# SSE315 register map
Vendor: ARM Ltd.; Series: ARMv8.1-M Mainline; File version: 1.0
CPU: CM85 r0p0, little endian, MPU, FPU, 3 interrupt priority bits, 8 SAU regions
Registers are 32-bit, read-write, reset 0x0 unless marked. A register's access mark holds for its fields unless they carry their own. Offsets are from the block's base; [hi:lo] are bit positions; {n}, {i} and the like mark numbered series.

## SAU — Security Attribution Unit
Base 0xE000EDD0
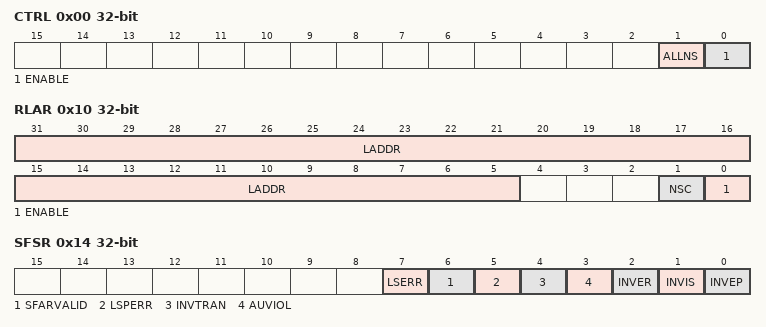
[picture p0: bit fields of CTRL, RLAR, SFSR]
0x00 CTRL — Control Register
  [1] ALLNS — Security attribution if SAU disabled
    0=Secure (Memory is marked as secure); 1=Non_Secure (Memory is marked as non-secure)
  [0] ENABLE
    0=Disable (SAU is disabled); 1=Enable (SAU is enabled)
0x04 TYPE ro
  [7:0] SREGION — Number of implemented SAU regions
0x08 RNR — Region Number Register
  [7:0] REGION — Currently selected SAU region
    {v}=SAU_Region_{v} (Select SAU Region {v}) (v=0..3)
0x0C RBAR — Region Base Address Register
  [31:5] BADDR — Base Address
0x10 RLAR — Region Limit Address Register
  [31:5] LADDR — Limit Address
  [1] NSC — Non-Secure Callable
  [0] ENABLE — SAU Region enabled
0x14 SFSR — Secure Fault Status Register
  [7] LSERR — Lazy state error flag
  [6] SFARVALID — Secure fault address valid
  [5] LSPERR — Lazy state preservation error flag
  [4] INVTRAN — Invalid transition flag
  [3] AUVIOL — Attribution unit violation flag
  [2] INVER — Invalid exception return flag
  [1] INVIS — Invalid integrity signature flag
  [0] INVEP — Invalid entry pointd

## TIMER0
Base 0x48000000
Same registers: TIMER1 0x48001000, TIMER2 0x48002000, TIMER3 0x48003000, TIMER0_Secure 0x58000000, TIMER1_Secure 0x58001000, TIMER2_Secure 0x58002000, TIMER3_Secure 0x58003000
0x00 CNTPCTLOW ro — Physical Count Register Lower Word.
0x04 CNTPCTHIGH ro — Physical Count Register Higher Word.
0x10 CNTFRQ — Counter Frequency Register.
0x20 CNTP_CVAL_LOW — Timer Compare Value Lower Word Register.
0x24 CNTP_CVAL_HIGH — Timer Compare Value Higher Word Register.
0x28 CNTP_TVAL — Timer Value register.
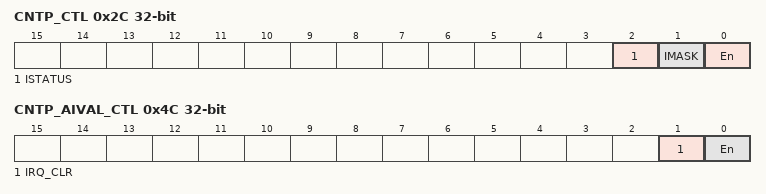
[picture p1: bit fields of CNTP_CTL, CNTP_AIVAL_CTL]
0x2C CNTP_CTL — Timer Control register.
  [all] fields
    0=Off; 1=On
  [2] ISTATUS — Interrupt Status
  [1] IMASK — Interrupt Mask
  [0] En — Enable Counter
0x40 CNTP_AIVAL_LOW ro — AutoIncrValue Lower Word Register.
0x44 CNTP_AIVAL_HIGH ro — AutoIncrValue Higher Word Register.
0x48 CNTP_AIVAL_RELOAD — AutoIncrValue Reload register.
0x4C CNTP_AIVAL_CTL — AutoIncrValue Control register.
  [1] IRQ_CLR — Interrupt Clear
    0=Nop; 1=Clear
  [0] En — Enable AutoIncrement.
    0=Off; 1=On
0x50 CNTP_CFG — Timer Configuration register.
0xFD0 PIDR4 ro reset 0x4 — Peripheral ID 4
0xFE0 PIDR0 ro reset 0xB7 — Peripheral ID 0
0xFE4 PIDR1 ro reset 0xB0 — Peripheral ID 1
0xFE8 PIDR2 ro reset 0xB — Peripheral ID 2
0xFEC PIDR3 ro — Peripheral ID 3
0xFF0 CIDR0 ro reset 0xD — Component ID 0
0xFF4 CIDR1 ro reset 0xF0 — Component ID 1
0xFF8 CIDR2 ro reset 0x5 — Component ID 2
0xFFC CIDR3 ro reset 0xB1 — Component ID 3

## SLOWCLK — SLOWCLK AON Timer
Base 0x4802F000
Same registers: SLOWCLKWATCHDOG 0x5802E000, SLOWCLK_Secure 0x5802F000
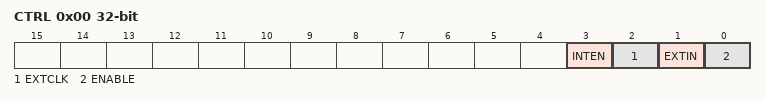
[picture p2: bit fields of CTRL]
0x00 CTRL — Control Register
  [3] INTEN — Interrupt Enable
    0=Disable (Interrupt is disabled); 1=Enable (Interrupt is enabled)
  [2] EXTCLK — External Clock Enable
    0=Disable (External Clock is disabled); 1=Enable (External Clock is enabled)
  [1] EXTIN — External Input as Enable
    0=Disable (External Input as Enable is disabled); 1=Enable (External Input as Enable is enabled)
  [0] ENABLE
    0=Disable (Timer is disabled); 1=Enable (Timer is enabled)
0x04 VALUE — Current Timer Counter Value
0x08 RELOAD — Counter Reload Value
0x0C INTSTATUS ro — Timer Interrupt status register
0x0C INTCLEAR wo write-1-clears (alternate view of INTSTATUS) — Timer Interrupt clear register

## GPIO0 — General-purpose I/O 0
Base 0x41100000
Same registers: GPIO1 0x41101000, GPIO2 0x41102000, GPIO3 0x41103000, GPIO0_Secure 0x50100000, GPIO1_Secure 0x50101000, GPIO2_Secure 0x50102000, GPIO3_Secure 0x50103000
0x00 DATA
0x04 DATAOUT — Data Output Register
0x10 OUTENSET — Ouptut enable set Register
0x14 OUTENCLR — Ouptut enable clear Register
0x18 ALTFUNCSET — Alternate function set Register
0x1C ALTFUNCCLR — Alternate function clear Register
0x20 INTENSET — Interrupt enable set Register
0x24 INTENCLR — Interrupt enable clear Register
0x28 INTTYPESET — Interrupt type set Register
0x2C INTTYPECLR — Interrupt type clear Register
0x30 INTPOLSET — Polarity-level, edge interrupt configuration set Register
0x34 INTPOLCLR — Polarity-level, edge interrupt configuration clear Register
0x38 INTSTATUS ro — Interrupt Status Register
0x38 INTCLEAR wo write-1-clears (alternate view of INTSTATUS) — Interrupt CLEAR Register

## Notices in the file
Copyright (C) 2012-2022 ARM Limited. All rights reserved.
Purpose: System Viewer Description (SVD) Example (Schema Version 1.1)
This is a description of a none-existent and incomplete device
for demonstration purposes only.
Redistribution and use in source and binary forms, with or without
modification, are permitted provided that the following conditions are met:
- Redistributions of source code must retain the above copyright
notice, this list of conditions and the following disclaimer.
- Redistributions in binary form must reproduce the above copyright
notice, this list of conditions and the following disclaimer in the
documentation and/or other materials provided with the distribution.
- Neither the name of ARM nor the names of its contributors may be used
to endorse or promote products derived from this software without
specific prior written permission.
THIS SOFTWARE IS PROVIDED BY THE COPYRIGHT HOLDERS AND CONTRIBUTORS "AS IS"
AND ANY EXPRESS OR IMPLIED WARRANTIES, INCLUDING, BUT NOT LIMITED TO, THE
IMPLIED WARRANTIES OF MERCHANTABILITY AND FITNESS FOR A PARTICULAR PURPOSE
ARE DISCLAIMED. IN NO EVENT SHALL COPYRIGHT HOLDERS AND CONTRIBUTORS BE
LIABLE FOR ANY DIRECT, INDIRECT, INCIDENTAL, SPECIAL, EXEMPLARY, OR
CONSEQUENTIAL DAMAGES (INCLUDING, BUT NOT LIMITED TO, PROCUREMENT OF
SUBSTITUTE GOODS OR SERVICES; LOSS OF USE, DATA, OR PROFITS; OR BUSINESS
INTERRUPTION) HOWEVER CAUSED AND ON ANY THEORY OF LIABILITY, WHETHER IN
CONTRACT, STRICT LIABILITY, OR TORT (INCLUDING NEGLIGENCE OR OTHERWISE)
ARISING IN ANY WAY OUT OF THE USE OF THIS SOFTWARE, EVEN IF ADVISED OF THE
POSSIBILITY OF SUCH DAMAGE.
